# ing916 register map
Vendor: INGChips; Series: ing916xx; File version: 522
CPU: CM4 r0p1, little endian, MPU, FPU, VTOR, 5 interrupt priority bits
Registers are 32-bit, read-write, reset 0x0 unless marked. A register's access mark holds for its fields unless they carry their own. Offsets are from the block's base; [hi:lo] are bit positions; {n}, {i} and the like mark numbered series.

## sys_ctrl
Base 0x40000000
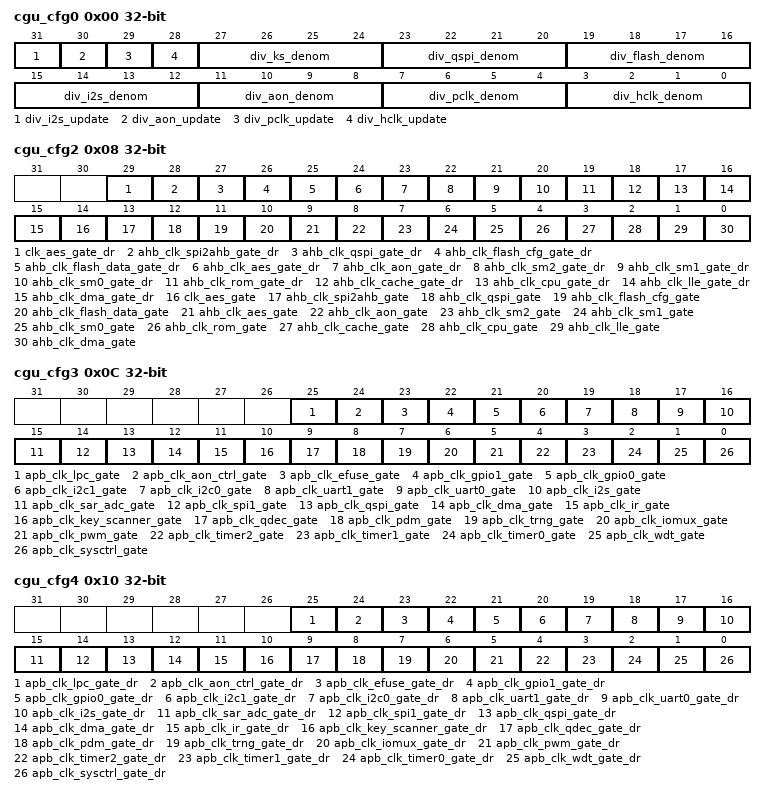
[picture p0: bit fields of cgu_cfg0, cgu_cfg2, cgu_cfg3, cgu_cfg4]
0x00 cgu_cfg0 — reg description:
  [31] div_i2s_update — reg description:
  [30] div_aon_update — reg description:
  [29] div_pclk_update — reg description:
  [28] div_hclk_update — reg description:
  [27:24] div_ks_denom — reg description:
  [23:20] div_qspi_denom — reg description:
  [19:16] div_flash_denom — reg description:
  [15:12] div_i2s_denom — reg description:
  [11:8] div_aon_denom — reg description:
  [7:4] div_pclk_denom — reg description:
  [3:0] div_hclk_denom — reg description:
0x04 cgu_cfg1 — reg description:
0x08 cgu_cfg2 — reg description:
  [29] clk_aes_gate_dr — reg description:
  [28] ahb_clk_spi2ahb_gate_dr — reg description:
  [27] ahb_clk_qspi_gate_dr — reg description:
  [26] ahb_clk_flash_cfg_gate_dr — reg description:
  [25] ahb_clk_flash_data_gate_dr — reg description:
  [24] ahb_clk_aes_gate_dr — reg description:
  [23] ahb_clk_aon_gate_dr — reg description:
  [22] ahb_clk_sm2_gate_dr — reg description:
  [21] ahb_clk_sm1_gate_dr — reg description:
  [20] ahb_clk_sm0_gate_dr — reg description:
  [19] ahb_clk_rom_gate_dr — reg description:
  [18] ahb_clk_cache_gate_dr — reg description:
  [17] ahb_clk_cpu_gate_dr — reg description:
  [16] ahb_clk_lle_gate_dr — reg description:
  [15] ahb_clk_dma_gate_dr — reg description:
  [14] clk_aes_gate — reg description:
  [13] ahb_clk_spi2ahb_gate — reg description:
  [12] ahb_clk_qspi_gate — reg description:
  [11] ahb_clk_flash_cfg_gate — reg description:
  [10] ahb_clk_flash_data_gate — reg description:
  [9] ahb_clk_aes_gate — reg description:
  [8] ahb_clk_aon_gate — reg description:
  [7] ahb_clk_sm2_gate — reg description:
  [6] ahb_clk_sm1_gate — reg description:
  [5] ahb_clk_sm0_gate — reg description:
  [4] ahb_clk_rom_gate — reg description:
  [3] ahb_clk_cache_gate — reg description:
  [2] ahb_clk_cpu_gate — reg description:
  [1] ahb_clk_lle_gate — reg description:
  [0] ahb_clk_dma_gate — reg description:
0x0C cgu_cfg3 — reg description:
  [25] apb_clk_lpc_gate — reg description:
  [24] apb_clk_aon_ctrl_gate — reg description:
  [23] apb_clk_efuse_gate — reg description:
  [22] apb_clk_gpio1_gate — reg description:
  [21] apb_clk_gpio0_gate — reg description:
  [20] apb_clk_i2c1_gate — reg description:
  [19] apb_clk_i2c0_gate — reg description:
  [18] apb_clk_uart1_gate — reg description:
  [17] apb_clk_uart0_gate — reg description:
  [16] apb_clk_i2s_gate — reg description:
  [15] apb_clk_sar_adc_gate — reg description:
  [14] apb_clk_spi1_gate — reg description:
  [13] apb_clk_qspi_gate — reg description:
  [12] apb_clk_dma_gate — reg description:
  [11] apb_clk_ir_gate — reg description:
  [10] apb_clk_key_scanner_gate — reg description:
  [9] apb_clk_qdec_gate — reg description:
  [8] apb_clk_pdm_gate — reg description:
  [7] apb_clk_trng_gate — reg description:
  [6] apb_clk_iomux_gate — reg description:
  [5] apb_clk_pwm_gate — reg description:
  [4] apb_clk_timer2_gate — reg description:
  [3] apb_clk_timer1_gate — reg description:
  [2] apb_clk_timer0_gate — reg description:
  [1] apb_clk_wdt_gate — reg description:
  [0] apb_clk_sysctrl_gate — reg description:
0x10 cgu_cfg4 — reg description:
  [25] apb_clk_lpc_gate_dr — reg description:
  [24] apb_clk_aon_ctrl_gate_dr — reg description:
  [23] apb_clk_efuse_gate_dr — reg description:
  [22] apb_clk_gpio1_gate_dr — reg description:
  [21] apb_clk_gpio0_gate_dr — reg description:
  [20] apb_clk_i2c1_gate_dr — reg description:
  [19] apb_clk_i2c0_gate_dr — reg description:
  [18] apb_clk_uart1_gate_dr — reg description:
  [17] apb_clk_uart0_gate_dr — reg description:
  [16] apb_clk_i2s_gate_dr — reg description:
  [15] apb_clk_sar_adc_gate_dr — reg description:
  [14] apb_clk_spi1_gate_dr — reg description:
  [13] apb_clk_qspi_gate_dr — reg description:
  [12] apb_clk_dma_gate_dr — reg description:
  [11] apb_clk_ir_gate_dr — reg description:
  [10] apb_clk_key_scanner_gate_dr — reg description:
  [9] apb_clk_qdec_gate_dr — reg description:
  [8] apb_clk_pdm_gate_dr — reg description:
  [7] apb_clk_trng_gate_dr — reg description:
  [6] apb_clk_iomux_gate_dr — reg description:
  [5] apb_clk_pwm_gate_dr — reg description:
  [4] apb_clk_timer2_gate_dr — reg description:
  [3] apb_clk_timer1_gate_dr — reg description:
  [2] apb_clk_timer0_gate_dr — reg description:
  [1] apb_clk_wdt_gate_dr — reg description:
  [0] apb_clk_sysctrl_gate_dr — reg description:
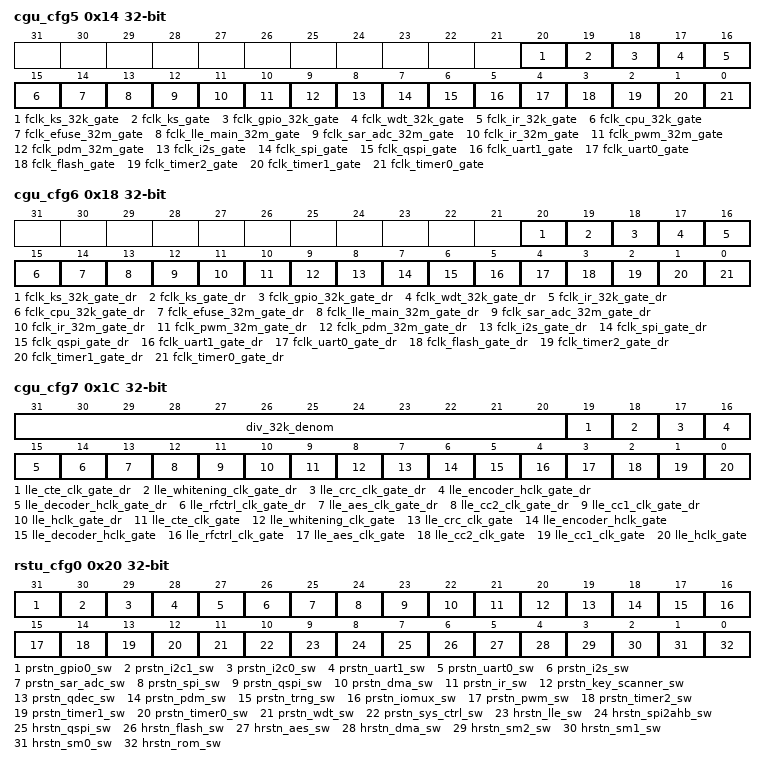
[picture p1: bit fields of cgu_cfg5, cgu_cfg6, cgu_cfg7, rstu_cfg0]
0x14 cgu_cfg5 — reg description:
  [20] fclk_ks_32k_gate — reg description:
  [19] fclk_ks_gate — reg description:
  [18] fclk_gpio_32k_gate — reg description:
  [17] fclk_wdt_32k_gate — reg description:
  [16] fclk_ir_32k_gate — reg description:
  [15] fclk_cpu_32k_gate — reg description:
  [14] fclk_efuse_32m_gate — reg description:
  [13] fclk_lle_main_32m_gate — reg description:
  [12] fclk_sar_adc_32m_gate — reg description:
  [11] fclk_ir_32m_gate — reg description:
  [10] fclk_pwm_32m_gate — reg description:
  [9] fclk_pdm_32m_gate — reg description:
  [8] fclk_i2s_gate — reg description:
  [7] fclk_spi_gate — reg description:
  [6] fclk_qspi_gate — reg description:
  [5] fclk_uart1_gate — reg description:
  [4] fclk_uart0_gate — reg description:
  [3] fclk_flash_gate — reg description:
  [2] fclk_timer2_gate — reg description:
  [1] fclk_timer1_gate — reg description:
  [0] fclk_timer0_gate — reg description:
0x18 cgu_cfg6 — reg description:
  [20] fclk_ks_32k_gate_dr — reg description:
  [19] fclk_ks_gate_dr — reg description:
  [18] fclk_gpio_32k_gate_dr — reg description:
  [17] fclk_wdt_32k_gate_dr — reg description:
  [16] fclk_ir_32k_gate_dr — reg description:
  [15] fclk_cpu_32k_gate_dr — reg description:
  [14] fclk_efuse_32m_gate_dr — reg description:
  [13] fclk_lle_main_32m_gate_dr — reg description:
  [12] fclk_sar_adc_32m_gate_dr — reg description:
  [11] fclk_ir_32m_gate_dr — reg description:
  [10] fclk_pwm_32m_gate_dr — reg description:
  [9] fclk_pdm_32m_gate_dr — reg description:
  [8] fclk_i2s_gate_dr — reg description:
  [7] fclk_spi_gate_dr — reg description:
  [6] fclk_qspi_gate_dr — reg description:
  [5] fclk_uart1_gate_dr — reg description:
  [4] fclk_uart0_gate_dr — reg description:
  [3] fclk_flash_gate_dr — reg description:
  [2] fclk_timer2_gate_dr — reg description:
  [1] fclk_timer1_gate_dr — reg description:
  [0] fclk_timer0_gate_dr — reg description:
0x1C cgu_cfg7 — reg description:
  [31:20] div_32k_denom — reg description:
  [19] lle_cte_clk_gate_dr — reg description:
  [18] lle_whitening_clk_gate_dr — reg description:
  [17] lle_crc_clk_gate_dr — reg description:
  [16] lle_encoder_hclk_gate_dr — reg description:
  [15] lle_decoder_hclk_gate_dr — reg description:
  [14] lle_rfctrl_clk_gate_dr — reg description:
  [13] lle_aes_clk_gate_dr — reg description:
  [12] lle_cc2_clk_gate_dr — reg description:
  [11] lle_cc1_clk_gate_dr — reg description:
  [10] lle_hclk_gate_dr — reg description:
  [9] lle_cte_clk_gate — reg description:
  [8] lle_whitening_clk_gate — reg description:
  [7] lle_crc_clk_gate — reg description:
  [6] lle_encoder_hclk_gate — reg description:
  [5] lle_decoder_hclk_gate — reg description:
  [4] lle_rfctrl_clk_gate — reg description:
  [3] lle_aes_clk_gate — reg description:
  [2] lle_cc2_clk_gate — reg description:
  [1] lle_cc1_clk_gate — reg description:
  [0] lle_hclk_gate — reg description:
0x20 rstu_cfg0 — reg description:
  [31] prstn_gpio0_sw — reg description:
  [30] prstn_i2c1_sw — reg description:
  [29] prstn_i2c0_sw — reg description:
  [28] prstn_uart1_sw — reg description:
  [27] prstn_uart0_sw — reg description:
  [26] prstn_i2s_sw — reg description:
  [25] prstn_sar_adc_sw — reg description:
  [24] prstn_spi_sw — reg description:
  [23] prstn_qspi_sw — reg description:
  [22] prstn_dma_sw — reg description:
  [21] prstn_ir_sw — reg description:
  [20] prstn_key_scanner_sw — reg description:
  [19] prstn_qdec_sw — reg description:
  [18] prstn_pdm_sw — reg description:
  [17] prstn_trng_sw — reg description:
  [16] prstn_iomux_sw — reg description:
  [15] prstn_pwm_sw — reg description:
  [14] prstn_timer2_sw — reg description:
  [13] prstn_timer1_sw — reg description:
  [12] prstn_timer0_sw — reg description:
  [11] prstn_wdt_sw — reg description:
  [10] prstn_sys_ctrl_sw — reg description:
  [9] hrstn_lle_sw — reg description:
  [8] hrstn_spi2ahb_sw — reg description:
  [7] hrstn_qspi_sw — reg description:
  [6] hrstn_flash_sw — reg description:
  [5] hrstn_aes_sw — reg description:
  [4] hrstn_dma_sw — reg description:
  [3] hrstn_sm2_sw — reg description:
  [2] hrstn_sm1_sw — reg description:
  [1] hrstn_sm0_sw — reg description:
  [0] hrstn_rom_sw — reg description:
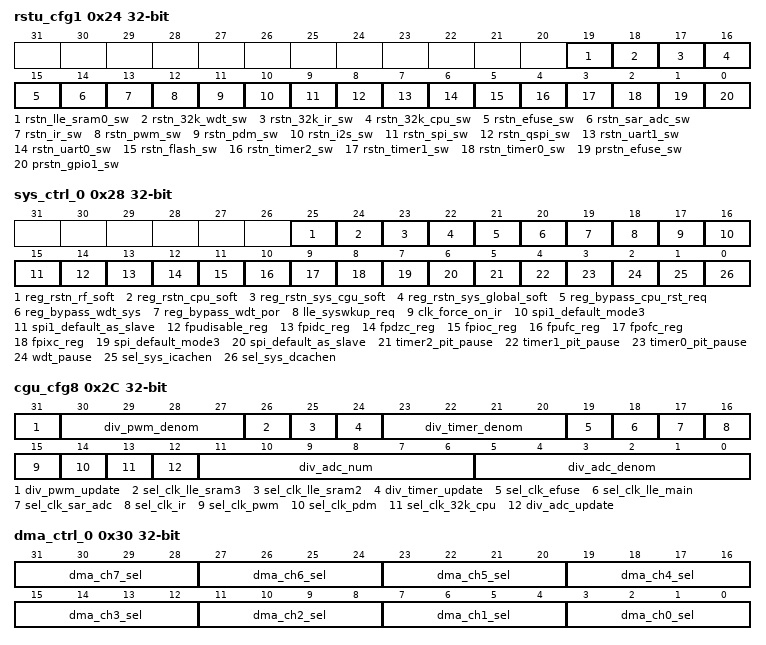
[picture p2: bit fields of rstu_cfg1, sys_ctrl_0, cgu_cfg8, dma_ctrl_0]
0x24 rstu_cfg1 — reg description:
  [19] rstn_lle_sram0_sw — reg description:
  [18] rstn_32k_wdt_sw — reg description:
  [17] rstn_32k_ir_sw — reg description:
  [16] rstn_32k_cpu_sw — reg description:
  [15] rstn_efuse_sw — reg description:
  [14] rstn_sar_adc_sw — reg description:
  [13] rstn_ir_sw — reg description:
  [12] rstn_pwm_sw — reg description:
  [11] rstn_pdm_sw — reg description:
  [10] rstn_i2s_sw — reg description:
  [9] rstn_spi_sw — reg description:
  [8] rstn_qspi_sw — reg description:
  [7] rstn_uart1_sw — reg description:
  [6] rstn_uart0_sw — reg description:
  [5] rstn_flash_sw — reg description:
  [4] rstn_timer2_sw — reg description:
  [3] rstn_timer1_sw — reg description:
  [2] rstn_timer0_sw — reg description:
  [1] prstn_efuse_sw — reg description:
  [0] prstn_gpio1_sw — reg description:
0x28 sys_ctrl_0 — reg description:
  [25] reg_rstn_rf_soft — reg description:
  [24] reg_rstn_cpu_soft — reg description:
  [23] reg_rstn_sys_cgu_soft — reg description:
  [22] reg_rstn_sys_global_soft — reg description:
  [21] reg_bypass_cpu_rst_req — reg description:
  [20] reg_bypass_wdt_sys — reg description:
  [19] reg_bypass_wdt_por — reg description:
  [18] lle_syswkup_req — reg description:
  [17] clk_force_on_ir — reg description:
  [16] spi1_default_mode3 — reg description:
  [15] spi1_default_as_slave — reg description:
  [14] fpudisable_reg — reg description:
  [13] fpidc_reg — reg description:
  [12] fpdzc_reg — reg description:
  [11] fpioc_reg — reg description:
  [10] fpufc_reg — reg description:
  [9] fpofc_reg — reg description:
  [8] fpixc_reg — reg description:
  [7] spi_default_mode3 — reg description:
  [6] spi_default_as_slave — reg description:
  [5] timer2_pit_pause — reg description:
  [4] timer1_pit_pause — reg description:
  [3] timer0_pit_pause — reg description:
  [2] wdt_pause — reg description:
  [1] sel_sys_icachen — reg description:
  [0] sel_sys_dcachen — reg description:
0x2C cgu_cfg8 — reg description:
  [31] div_pwm_update — reg description:
  [30:27] div_pwm_denom — reg description:
  [26] sel_clk_lle_sram3 — reg description:
  [25] sel_clk_lle_sram2 — reg description:
  [24] div_timer_update — reg description:
  [23:20] div_timer_denom — reg description:
  [19] sel_clk_efuse — reg description:
  [18] sel_clk_lle_main — reg description:
  [17] sel_clk_sar_adc — reg description:
  [16] sel_clk_ir — reg description:
  [15] sel_clk_pwm — reg description:
  [14] sel_clk_pdm — reg description:
  [13] sel_clk_32k_cpu — reg description:
  [12] div_adc_update — reg description:
  [11:6] div_adc_num — reg description:
  [5:0] div_adc_denom — reg description:
0x30 dma_ctrl_0 — reg description:
  [4n+3:4n] dma_ch{n}_sel (n=0..7) — reg description:
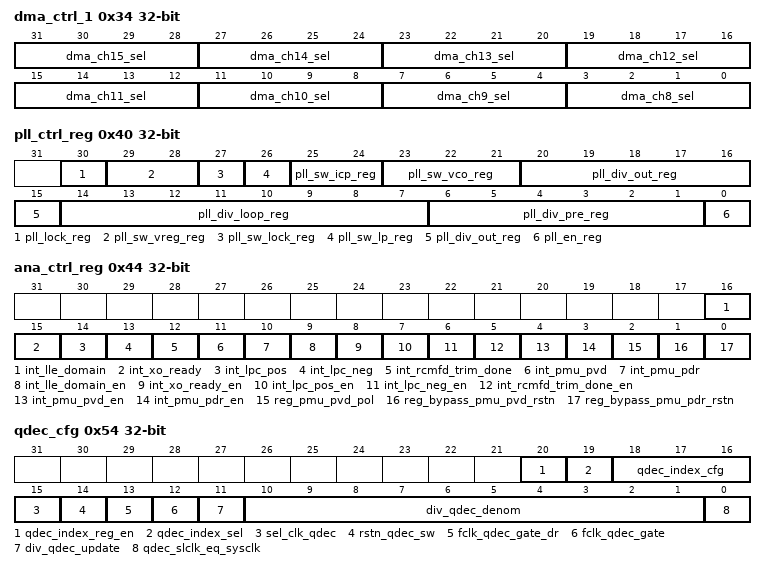
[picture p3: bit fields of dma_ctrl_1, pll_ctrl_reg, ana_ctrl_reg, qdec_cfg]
0x34 dma_ctrl_1 — reg description:
  [4n-29:4n-32] dma_ch{n}_sel (n=8..15) — reg description:
0x40 pll_ctrl_reg — reg description:
  [30] pll_lock_reg — reg description:
  [29:28] pll_sw_vreg_reg — reg description:
  [27] pll_sw_lock_reg — reg description:
  [26] pll_sw_lp_reg — reg description:
  [25:24] pll_sw_icp_reg — reg description:
  [23:21] pll_sw_vco_reg — reg description:
  [20:15] pll_div_out_reg — reg description:
  [14:7] pll_div_loop_reg — reg description:
  [6:1] pll_div_pre_reg — reg description:
  [0] pll_en_reg — reg description:
0x44 ana_ctrl_reg — reg description:
  [16] int_lle_domain — reg description:
  [15] int_xo_ready — reg description:
  [14] int_lpc_pos — reg description:
  [13] int_lpc_neg — reg description:
  [12] int_rcmfd_trim_done — reg description:
  [11] int_pmu_pvd — reg description:
  [10] int_pmu_pdr — reg description:
  [9] int_lle_domain_en — reg description:
  [8] int_xo_ready_en — reg description:
  [7] int_lpc_pos_en — reg description:
  [6] int_lpc_neg_en — reg description:
  [5] int_rcmfd_trim_done_en — reg description:
  [4] int_pmu_pvd_en — reg description:
  [3] int_pmu_pdr_en — reg description:
  [2] reg_pmu_pvd_pol — reg description:
  [1] reg_bypass_pmu_pvd_rstn — reg description:
  [0] reg_bypass_pmu_pdr_rstn — reg description:
0x50 pdm_i2s_ctrl — reg description:
  [0] i2s_from_pdm
0x54 qdec_cfg — reg description:
  [20] qdec_index_reg_en — reg description:
  [19] qdec_index_sel — reg description:
  [18:16] qdec_index_cfg — reg description:
  [15] sel_clk_qdec — reg description:
  [14] rstn_qdec_sw — reg description:
  [13] fclk_qdec_gate_dr — reg description:
  [12] fclk_qdec_gate — reg description:
  [11] div_qdec_update — reg description:
  [10:1] div_qdec_denom — reg description:
  [0] qdec_slclk_eq_sysclk — reg description:
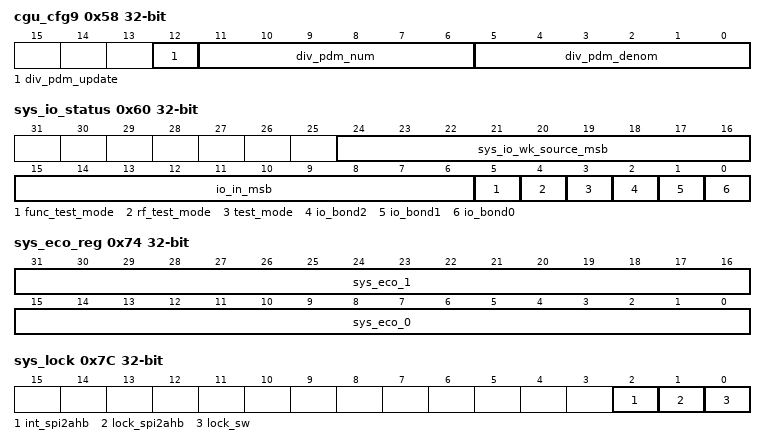
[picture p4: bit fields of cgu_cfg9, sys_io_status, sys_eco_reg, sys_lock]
0x58 cgu_cfg9 — reg description:
  [12] div_pdm_update — reg description:
  [11:6] div_pdm_num — reg description:
  [5:0] div_pdm_denom — reg description:
0x60 sys_io_status — reg description:
  [24:16] sys_io_wk_source_msb — reg description:
  [15:6] io_in_msb — reg description:
  [5] func_test_mode — reg description:
  [4] rf_test_mode — reg description:
  [3] test_mode — reg description:
  [2] io_bond2 — reg description:
  [1] io_bond1 — reg description:
  [0] io_bond0 — reg description:
0x64 sys_io_wk_source — reg description:
  [31:0] sys_io_wk_source_lsb
0x68 sys_io_in_status — reg description:
  [31:0] io_in_lsb
0x74 sys_eco_reg — reg description:
  [31:16] sys_eco_1 — reg description:
  [15:0] sys_eco_0 — reg description:
0x7C sys_lock — reg description:
  [2] int_spi2ahb — reg description:
  [1] lock_spi2ahb — reg description:
  [0] lock_sw — reg description:
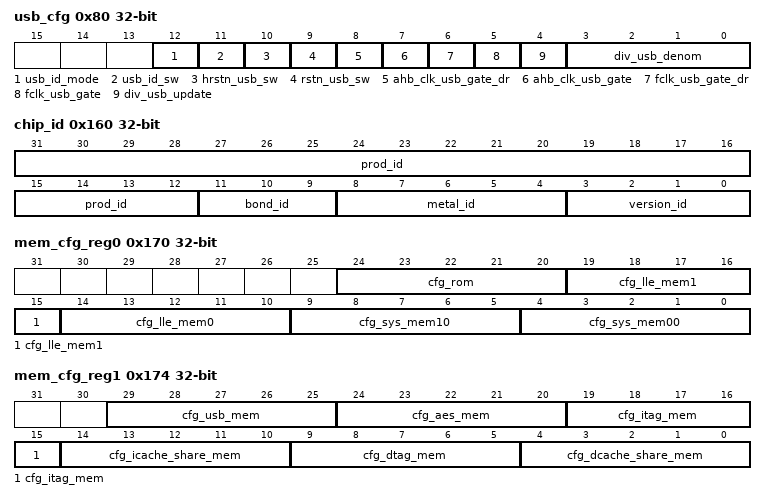
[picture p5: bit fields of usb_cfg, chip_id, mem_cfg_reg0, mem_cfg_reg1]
0x80 usb_cfg — reg description:
  [12] usb_id_mode — reg description:
  [11] usb_id_sw — reg description:
  [10] hrstn_usb_sw — reg description:
  [9] rstn_usb_sw — reg description:
  [8] ahb_clk_usb_gate_dr — reg description:
  [7] ahb_clk_usb_gate — reg description:
  [6] fclk_usb_gate_dr — reg description:
  [5] fclk_usb_gate — reg description:
  [4] div_usb_update — reg description:
  [3:0] div_usb_denom — reg description:
0x160 chip_id — reg description:
  [31:12] prod_id — reg description:
  [11:9] bond_id — reg description:
  [8:4] metal_id — reg description:
  [3:0] version_id — reg description:
0x170 mem_cfg_reg0 — reg description:
  [24:20] cfg_rom — reg description:
  [19:15] cfg_lle_mem1 — reg description:
  [14:10] cfg_lle_mem0 — reg description:
  [9:5] cfg_sys_mem10 — reg description:
  [4:0] cfg_sys_mem00 — reg description:
0x174 mem_cfg_reg1 — reg description:
  [29:25] cfg_usb_mem — reg description:
  [24:20] cfg_aes_mem — reg description:
  [19:15] cfg_itag_mem — reg description:
  [14:10] cfg_icache_share_mem — reg description:
  [9:5] cfg_dtag_mem — reg description:
  [4:0] cfg_dcache_share_mem — reg description:
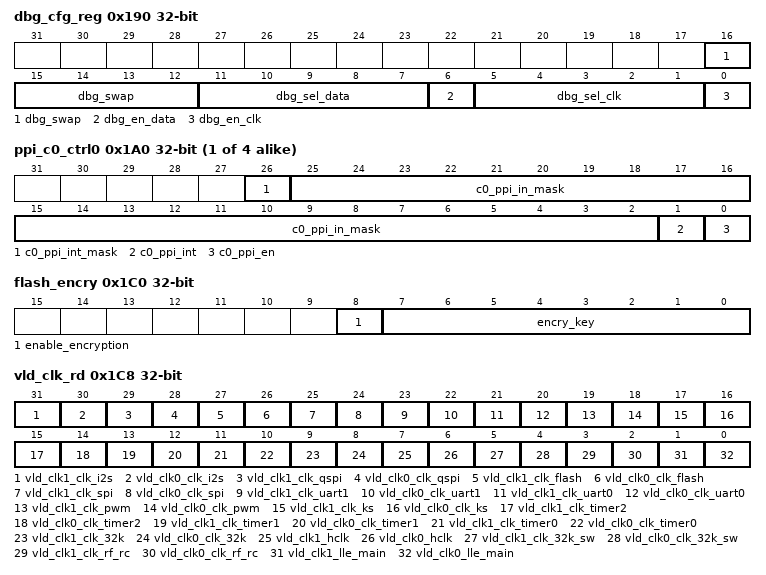
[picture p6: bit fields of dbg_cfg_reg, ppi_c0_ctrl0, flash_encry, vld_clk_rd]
0x190 dbg_cfg_reg — reg description:
  [16:12] dbg_swap — reg description:
  [11:7] dbg_sel_data — reg description:
  [6] dbg_en_data — reg description:
  [5:1] dbg_sel_clk — reg description:
  [0] dbg_en_clk — reg description:
{0x1A0+8i} ppi_c{i}_ctrl0 (i=0..3) — reg description:
  [26] c{i}_ppi_int_mask — reg description:
  [25:2] c{i}_ppi_in_mask — reg description:
  [1] c{i}_ppi_int — reg description:
  [0] c{i}_ppi_en — reg description:
{0x1A4+8i} ppi_c{i}_ctrl1 (i=0..3) — reg description:
  [15:0] c{i}_ppi_out_mask
0x1C0 flash_encry — reg description:
  [8] enable_encryption — reg description:
  [7:0] encry_key — reg description:
0x1C4 io_vdd_ok — reg description:
  [0] sys_io_vddok
0x1C8 vld_clk_rd — reg description:
  [31] vld_clk1_clk_i2s — reg description:
  [30] vld_clk0_clk_i2s — reg description:
  [29] vld_clk1_clk_qspi — reg description:
  [28] vld_clk0_clk_qspi — reg description:
  [27] vld_clk1_clk_flash — reg description:
  [26] vld_clk0_clk_flash — reg description:
  [25] vld_clk1_clk_spi — reg description:
  [24] vld_clk0_clk_spi — reg description:
  [23] vld_clk1_clk_uart1 — reg description:
  [22] vld_clk0_clk_uart1 — reg description:
  [21] vld_clk1_clk_uart0 — reg description:
  [20] vld_clk0_clk_uart0 — reg description:
  [19] vld_clk1_clk_pwm — reg description:
  [18] vld_clk0_clk_pwm — reg description:
  [17] vld_clk1_clk_ks — reg description:
  [16] vld_clk0_clk_ks — reg description:
  [15] vld_clk1_clk_timer2 — reg description:
  [14] vld_clk0_clk_timer2 — reg description:
  [13] vld_clk1_clk_timer1 — reg description:
  [12] vld_clk0_clk_timer1 — reg description:
  [11] vld_clk1_clk_timer0 — reg description:
  [10] vld_clk0_clk_timer0 — reg description:
  [9] vld_clk1_clk_32k — reg description:
  [8] vld_clk0_clk_32k — reg description:
  [7] vld_clk1_hclk — reg description:
  [6] vld_clk0_hclk — reg description:
  [5] vld_clk1_clk_32k_sw — reg description:
  [4] vld_clk0_clk_32k_sw — reg description:
  [3] vld_clk1_clk_rf_rc — reg description:
  [2] vld_clk0_clk_rf_rc — reg description:
  [1] vld_clk1_lle_main — reg description:
  [0] vld_clk0_lle_main — reg description:
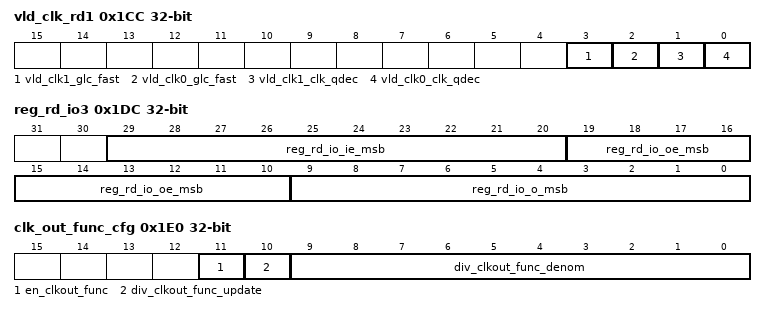
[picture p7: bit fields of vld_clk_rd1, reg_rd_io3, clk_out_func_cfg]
0x1CC vld_clk_rd1 — reg description:
  [3] vld_clk1_glc_fast — reg description:
  [2] vld_clk0_glc_fast — reg description:
  [1] vld_clk1_clk_qdec — reg description:
  [0] vld_clk0_clk_qdec — reg description:
0x1D0 reg_rd_io0 — reg description:
  [31:0] reg_rd_io_o_lsb
0x1D4 reg_rd_io1 — reg description:
  [31:0] reg_rd_io_oe_lsb
0x1D8 reg_rd_io2 — reg description:
  [31:0] reg_rd_io_ie_lsb
0x1DC reg_rd_io3 — reg description:
  [29:20] reg_rd_io_ie_msb — reg description:
  [19:10] reg_rd_io_oe_msb — reg description:
  [9:0] reg_rd_io_o_msb — reg description:
0x1E0 clk_out_func_cfg — reg description:
  [11] en_clkout_func — reg description:
  [10] div_clkout_func_update — reg description:
  [9:0] div_clkout_func_denom — reg description:
